# EZR32LG330F128R61 register map
File version: 4.0.0
CPU: CM3 r2p1, little endian, MPU, no FPU, 3 interrupt priority bits
Registers are 32-bit, read-write, reset 0x0 unless marked. A register's access mark holds for its fields unless they carry their own. Offsets are from the block's base; [hi:lo] are bit positions; {n}, {i} and the like mark numbered series.

## BURTC
Base 0x40081000
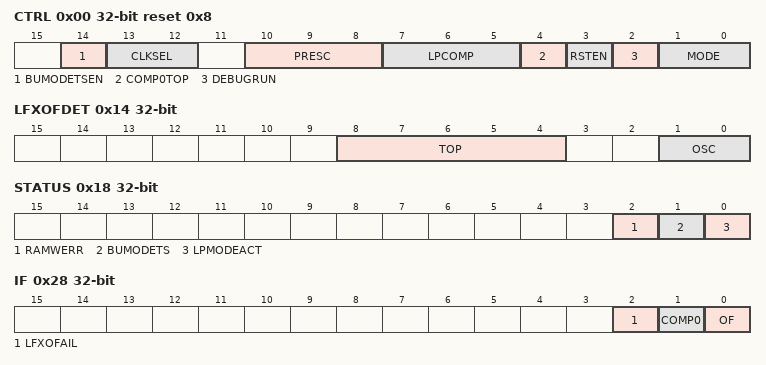
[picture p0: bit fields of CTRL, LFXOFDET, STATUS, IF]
0x00 CTRL reset 0x8 — Control Register
  [14] BUMODETSEN — Backup mode timestamp enable
  [13:12] CLKSEL — Select BURTC clock source
    0=NONE (No clock source selected for BURTC.); 1=LFRCO (LFRCO selected as BURTC clock source.); 2=LFXO (LFXO selected as BURTC clock source.); 3=ULFRCO (ULFRCO selected as BURTC clock source.)
  [10:8] PRESC — Select BURTC prescaler factor
    0=DIV1 (No prescaling.); 1=DIV2 (Prescaling factor of 2); 2=DIV4 (Prescaling factor of 4); 3=DIV8 (Prescaling factor of 8); 4=DIV16 (Prescaling factor of 16); 5=DIV32 (Prescaling factor of 32); 6=DIV64 (Prescaling factor of 64); 7=DIV128 (Prescaling factor of 128)
  [7:5] LPCOMP — Low power mode compare configuration
    0=IGN0LSB (Do not ignore any bits for compare match evaluation.); 1=IGN1LSB (The LSB of the counter is ignored for compare match evaluation.); 2=IGN2LSB (The two LSBs of the counter are ignored for compare match evaluation.); 3=IGN3LSB (The three LSBs of the counter are ignored for compare match evaluation.); 4=IGN4LSB (The four LSBs of the counter are ignored for compare match evaluation.); 5=IGN5LSB (The five LSBs of the counter are ignored for compare match evaluation.); 6=IGN6LSB (The six LSBs of the counter are ignored for compare match evaluation.); 7=IGN7LSB (The seven LSBs of the counter are ignored for compare match evaluation.)
  [4] COMP0TOP — Compare clear enable
  [3] RSTEN — Enable BURTC reset
  [2] DEBUGRUN — Debug Mode Run Enable
  [1:0] MODE — BURTC Enable
    0=DISABLE (The BURTC is disabled.); 1=EM2EN (The BURTC is in normal operating mode, operating in EM0-EM2. Oscillators must be enabled in CMU for use.); 2=EM3EN (The BURTC is enabled in EM0-EM3. Will prevent CMU from disabling used oscillators all the way down to EM3.); 3=EM4EN (The BURTC is enabled in EM0-EM4. Will prevent CMU from disabling used oscillators all the way down to EM4.)
0x04 LPMODE — Low power mode configuration
  [1:0] LPMODE — Low power mode configuration.
    0=DISABLE (Low power mode is disabled.); 1=ENABLE (Low power mode always enabled.); 2=BUEN (Low power mode enabled in backup mode.)
0x08 CNT ro — Counter Value Register
  [31:0] CNT — Counter Value
0x0C COMP0 — Counter Compare Value
  [31:0] COMP0 — Compare match value
0x10 TIMESTAMP ro — Backup mode timestamp
  [31:0] TIMESTAMP — Backup mode timestamp.
0x14 LFXOFDET — LFXO
  [8:4] TOP — LFXO failure counter top value.
  [1:0] OSC — LFXO failure detection configuration.
    0=DISABLE (LFXO failure detection disabled.); 1=LFRCO (LFRCO used for LFXO failure detection.); 2=ULFRCO (ULFRCO used for LFXO failure detection.)
0x18 STATUS ro
  [2] RAMWERR — RAM write error.
  [1] BUMODETS — Timestamp for backup mode entry stored.
  [0] LPMODEACT — Low power mode active
0x1C CMD wo — Command Register
  [0] CLRSTATUS — Clear BURTC_STATUS register.
0x20 POWERDOWN — Retention RAM power-down Register
  [0] RAM — Retention RAM power-down
0x24 LOCK — Configuration Lock Register
  [15:0] LOCKKEY — Configuration Lock Key
    0=UNLOCKED; 1=LOCKED
0x28 IF ro — Interrupt Flag Register
  [2] LFXOFAIL — LFXO failure Interrupt Flag
  [1] COMP0 — Compare match Interrupt Flag
  [0] OF — Overflow Interrupt Flag
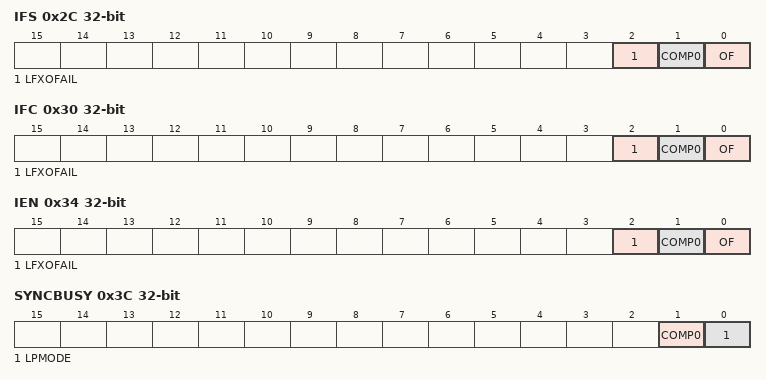
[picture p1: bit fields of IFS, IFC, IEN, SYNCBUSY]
0x2C IFS wo — Interrupt Flag Set Register
  [2] LFXOFAIL — Set LFXO fail Interrupt Flag
  [1] COMP0 — Set compare match Interrupt Flag
  [0] OF — Set Overflow Interrupt Flag
0x30 IFC wo — Interrupt Flag Clear Register
  [2] LFXOFAIL — Clear LFXO failure Interrupt Flag
  [1] COMP0 — Clear compare match Interrupt Flag
  [0] OF — Clear Overflow Interrupt Flag
0x34 IEN — Interrupt Enable Register
  [2] LFXOFAIL — LFXO failure Interrupt Enable
  [1] COMP0 — Compare match Interrupt Enable
  [0] OF — Overflow Interrupt Enable
0x38 FREEZE
  [0] REGFREEZE — Register Update Freeze
0x3C SYNCBUSY ro — Synchronization Busy Register
  [1] COMP0 — COMP0 Register Busy
  [0] LPMODE — LPMODE Register Busy
{0x100+4i} RET{i}_REG (i=0..127) — Retention Register
  [31:0] REG — General Purpose Retention Register

## Notices in the file
# License
Copyright 2021 Silicon Laboratories Inc. www.silabs.com
SPDX-License-Identifier: Zlib
The licensor of this software is Silicon Laboratories Inc.
This software is provided 'as-is', without any express or implied
warranty. In no event will the authors be held liable for any damages
arising from the use of this software.
Permission is granted to anyone to use this software for any purpose,
including commercial applications, and to alter it and redistribute it
freely, subject to the following restrictions:
1. The origin of this software must not be misrepresented; you must not
claim that you wrote the original software. If you use this software
in a product, an acknowledgment in the product documentation would be
appreciated but is not required.
2. Altered source versions must be plainly marked as such, and must not be
misrepresented as being the original software.
3. This notice may not be removed or altered from any source distribution.
